VERSION ""

NS_ :

BS_:

BU_: AMS VCU

BO_ 3221225472 VECTOR__INDEPENDENT_SIG_MSG: 0 Vector__XXX
 SG_ NewSignal_0003 : 24|8@1+ (1,0) [0|0] "" Vector__XXX

BO_ 131 Start_PreCharge: 1 VCU
 SG_ Precharge_Request : 0|1@0+ (1,0) [0|0] "ON/OFF" Vector__XXX

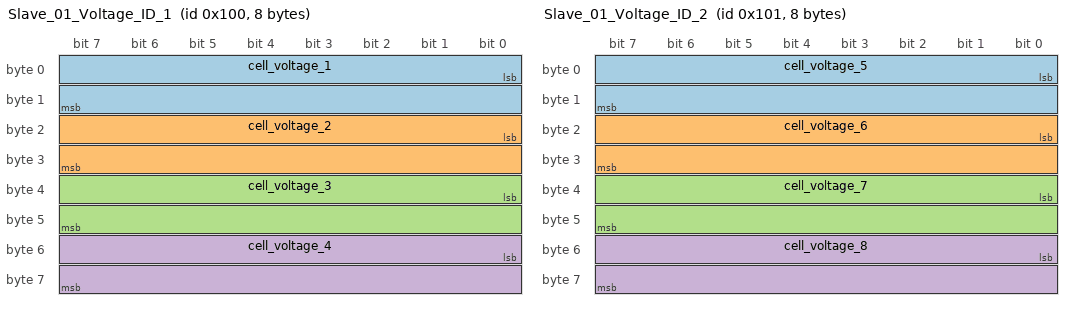
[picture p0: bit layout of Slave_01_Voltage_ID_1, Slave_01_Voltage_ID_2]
BO_ 256 Slave_01_Voltage_ID_1: 8 AMS
 SG_ cell_voltage_1 : 0|16@1+ (0.001,0) [0|0] "V" Vector__XXX
 SG_ cell_voltage_2 : 16|16@1+ (0.001,0) [0|0] "V" Vector__XXX
 SG_ cell_voltage_3 : 32|16@1+ (0.001,0) [0|0] "V" Vector__XXX
 SG_ cell_voltage_4 : 48|16@1+ (0.001,0) [0|0] "V" Vector__XXX

BO_ 257 Slave_01_Voltage_ID_2: 8 AMS
 SG_ cell_voltage_5 : 0|16@1+ (0.001,0) [0|0] "V" Vector__XXX
 SG_ cell_voltage_6 : 16|16@1+ (0.001,0) [0|0] "V" Vector__XXX
 SG_ cell_voltage_7 : 32|16@1+ (0.001,0) [0|0] "V" Vector__XXX
 SG_ cell_voltage_8 : 48|16@1+ (0.001,0) [0|0] "V" Vector__XXX

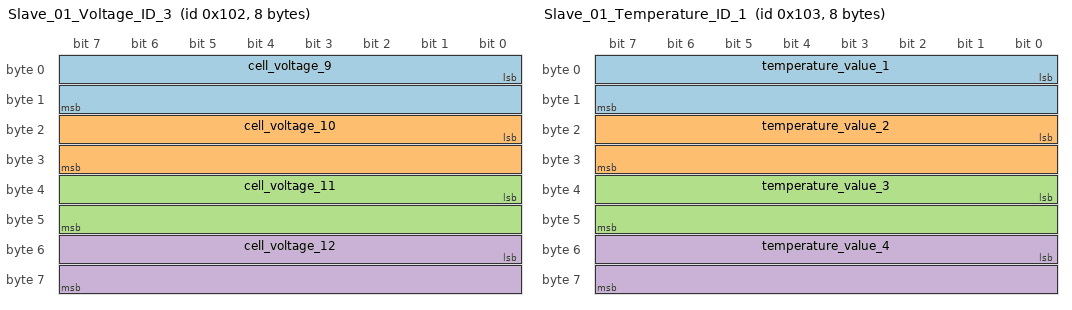
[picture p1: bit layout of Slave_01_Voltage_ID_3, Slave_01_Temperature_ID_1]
BO_ 258 Slave_01_Voltage_ID_3: 8 AMS
 SG_ cell_voltage_9 : 0|16@1+ (0.001,0) [0|0] "V" Vector__XXX
 SG_ cell_voltage_10 : 16|16@1+ (0.001,0) [0|0] "V" Vector__XXX
 SG_ cell_voltage_11 : 32|16@1+ (0.001,0) [0|0] "V" Vector__XXX
 SG_ cell_voltage_12 : 48|16@1+ (0.001,0) [0|0] "V" Vector__XXX

BO_ 259 Slave_01_Temperature_ID_1: 8 AMS
 SG_ temperature_value_1 : 0|16@1+ (0.01,0) [0|0] "ºC" Vector__XXX
 SG_ temperature_value_2 : 16|16@1+ (0.01,0) [0|0] "ºC" Vector__XXX
 SG_ temperature_value_3 : 32|16@1+ (0.01,0) [0|0] "ºC" Vector__XXX
 SG_ temperature_value_4 : 48|16@1+ (0.01,0) [0|0] "ºC" Vector__XXX

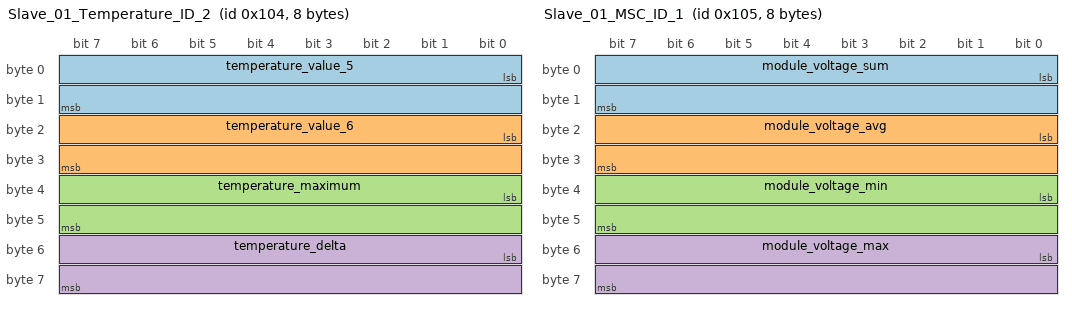
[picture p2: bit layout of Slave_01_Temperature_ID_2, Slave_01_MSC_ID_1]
BO_ 260 Slave_01_Temperature_ID_2: 8 AMS
 SG_ temperature_value_5 : 0|16@1+ (0.01,0) [0|0] "ºC" Vector__XXX
 SG_ temperature_value_6 : 16|16@1+ (0.01,0) [0|0] "ºC" Vector__XXX
 SG_ temperature_maximum : 32|16@1+ (0.01,0) [0|0] "ºC" Vector__XXX
 SG_ temperature_delta : 48|16@1+ (0.01,0) [0|0] "ºC" Vector__XXX

BO_ 261 Slave_01_MSC_ID_1: 8 AMS
 SG_ module_voltage_sum : 0|16@1+ (1,0) [0|0] "" Vector__XXX
 SG_ module_voltage_avg : 16|16@1+ (1,0) [0|0] "" Vector__XXX
 SG_ module_voltage_min : 32|16@1+ (1,0) [0|0] "" Vector__XXX
 SG_ module_voltage_max : 48|16@1+ (1,0) [0|0] "" Vector__XXX

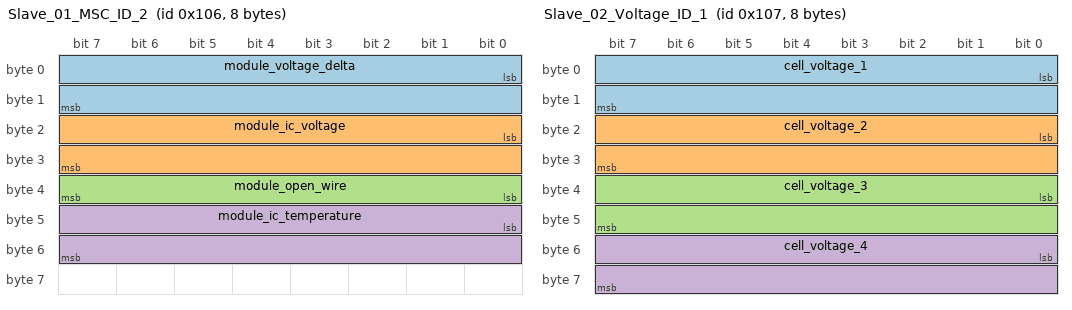
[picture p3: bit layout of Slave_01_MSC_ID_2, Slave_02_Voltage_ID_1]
BO_ 262 Slave_01_MSC_ID_2: 8 AMS
 SG_ module_voltage_delta : 0|16@1+ (1,0) [0|0] "" Vector__XXX
 SG_ module_ic_voltage : 16|16@1+ (1,0) [0|0] "" Vector__XXX
 SG_ module_open_wire : 32|8@1+ (1,0) [0|0] "" Vector__XXX
 SG_ module_ic_temperature : 40|16@1+ (1,0) [0|0] "" Vector__XXX

BO_ 263 Slave_02_Voltage_ID_1: 8 AMS
 SG_ cell_voltage_1 : 0|16@1+ (0.001,0) [0|0] "V" Vector__XXX
 SG_ cell_voltage_2 : 16|16@1+ (0.001,0) [0|0] "V" Vector__XXX
 SG_ cell_voltage_3 : 32|16@1+ (0.001,0) [0|0] "V" Vector__XXX
 SG_ cell_voltage_4 : 48|16@1+ (0.001,0) [0|0] "V" Vector__XXX

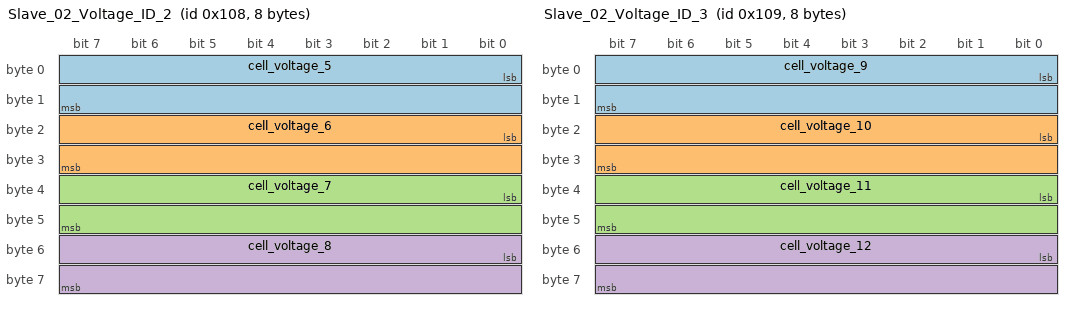
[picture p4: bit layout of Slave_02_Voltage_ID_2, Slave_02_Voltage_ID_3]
BO_ 264 Slave_02_Voltage_ID_2: 8 AMS
 SG_ cell_voltage_5 : 0|16@1+ (0.001,0) [0|0] "V" Vector__XXX
 SG_ cell_voltage_6 : 16|16@1+ (0.001,0) [0|0] "V" Vector__XXX
 SG_ cell_voltage_7 : 32|16@1+ (0.001,0) [0|0] "V" Vector__XXX
 SG_ cell_voltage_8 : 48|16@1+ (0.001,0) [0|0] "V" Vector__XXX

BO_ 265 Slave_02_Voltage_ID_3: 8 AMS
 SG_ cell_voltage_9 : 0|16@1+ (0.001,0) [0|0] "V" Vector__XXX
 SG_ cell_voltage_10 : 16|16@1+ (0.001,0) [0|0] "V" Vector__XXX
 SG_ cell_voltage_11 : 32|16@1+ (0.001,0) [0|0] "V" Vector__XXX
 SG_ cell_voltage_12 : 48|16@1+ (0.001,0) [0|0] "V" Vector__XXX

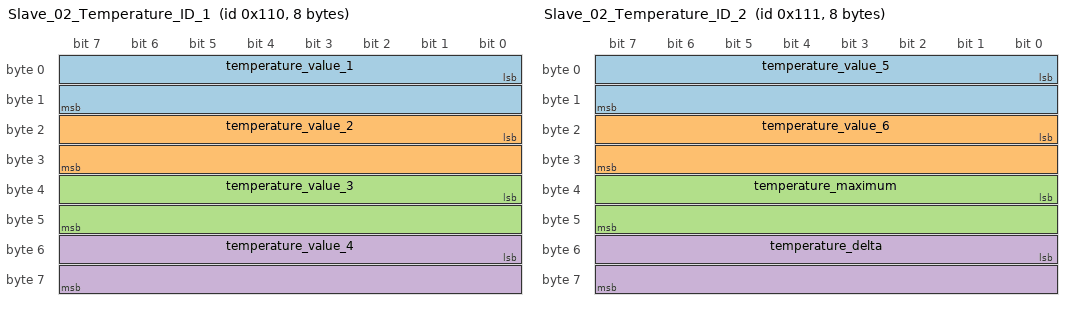
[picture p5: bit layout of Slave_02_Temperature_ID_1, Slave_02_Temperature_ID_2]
BO_ 272 Slave_02_Temperature_ID_1: 8 AMS
 SG_ temperature_value_1 : 0|16@1+ (0.01,0) [0|0] "ºC" Vector__XXX
 SG_ temperature_value_2 : 16|16@1+ (0.01,0) [0|0] "ºC" Vector__XXX
 SG_ temperature_value_3 : 32|16@1+ (0.01,0) [0|0] "ºC" Vector__XXX
 SG_ temperature_value_4 : 48|16@1+ (0.01,0) [0|0] "ºC" Vector__XXX

BO_ 273 Slave_02_Temperature_ID_2: 8 AMS
 SG_ temperature_value_5 : 0|16@1+ (0.01,0) [0|0] "ºC" Vector__XXX
 SG_ temperature_value_6 : 16|16@1+ (0.01,0) [0|0] "ºC" Vector__XXX
 SG_ temperature_maximum : 32|16@1+ (0.01,0) [0|0] "ºC" Vector__XXX
 SG_ temperature_delta : 48|16@1+ (0.01,0) [0|0] "ºC" Vector__XXX

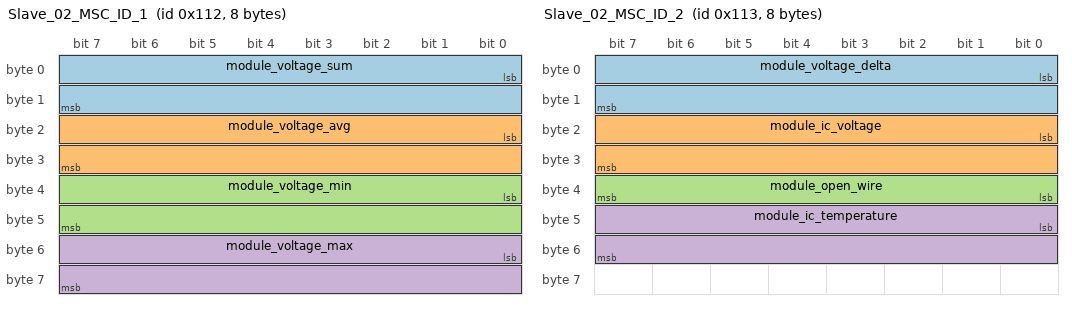
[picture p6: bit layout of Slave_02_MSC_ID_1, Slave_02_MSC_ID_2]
BO_ 274 Slave_02_MSC_ID_1: 8 AMS
 SG_ module_voltage_sum : 0|16@1+ (1,0) [0|0] "" Vector__XXX
 SG_ module_voltage_avg : 16|16@1+ (1,0) [0|0] "" Vector__XXX
 SG_ module_voltage_min : 32|16@1+ (1,0) [0|0] "" Vector__XXX
 SG_ module_voltage_max : 48|16@1+ (1,0) [0|0] "" Vector__XXX

BO_ 275 Slave_02_MSC_ID_2: 8 AMS
 SG_ module_voltage_delta : 0|16@1+ (1,0) [0|0] "" Vector__XXX
 SG_ module_ic_voltage : 16|16@1+ (1,0) [0|0] "" Vector__XXX
 SG_ module_open_wire : 32|8@1+ (1,0) [0|0] "" Vector__XXX
 SG_ module_ic_temperature : 40|16@1+ (1,0) [0|0] "" Vector__XXX

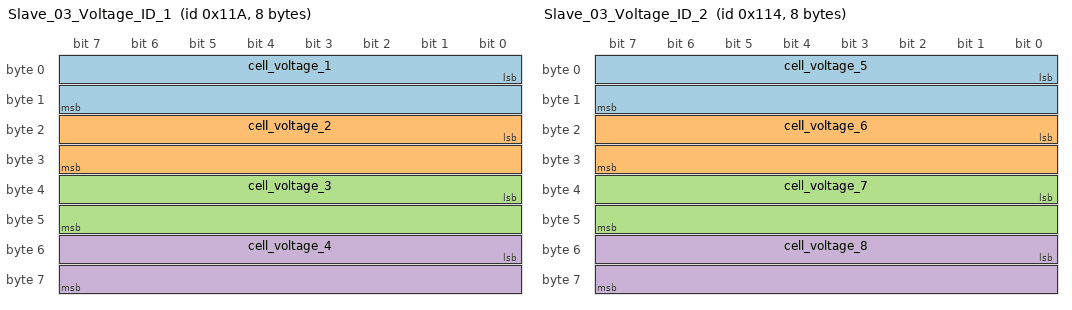
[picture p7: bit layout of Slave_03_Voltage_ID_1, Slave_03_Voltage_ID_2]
BO_ 282 Slave_03_Voltage_ID_1: 8 AMS
 SG_ cell_voltage_1 : 0|16@1+ (0.001,0) [0|0] "V" Vector__XXX
 SG_ cell_voltage_2 : 16|16@1+ (0.001,0) [0|0] "V" Vector__XXX
 SG_ cell_voltage_3 : 32|16@1+ (0.001,0) [0|0] "V" Vector__XXX
 SG_ cell_voltage_4 : 48|16@1+ (0.001,0) [0|0] "V" Vector__XXX

BO_ 276 Slave_03_Voltage_ID_2: 8 AMS
 SG_ cell_voltage_5 : 0|16@1+ (0.001,0) [0|0] "V" Vector__XXX
 SG_ cell_voltage_6 : 16|16@1+ (0.001,0) [0|0] "V" Vector__XXX
 SG_ cell_voltage_7 : 32|16@1+ (0.001,0) [0|0] "V" Vector__XXX
 SG_ cell_voltage_8 : 48|16@1+ (0.001,0) [0|0] "V" Vector__XXX

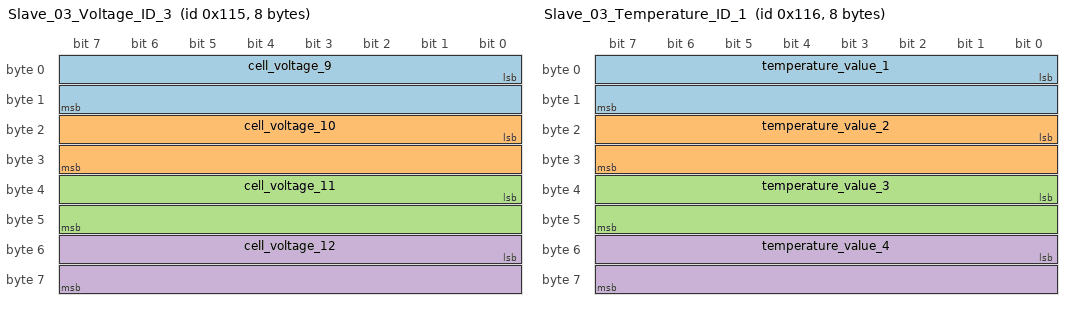
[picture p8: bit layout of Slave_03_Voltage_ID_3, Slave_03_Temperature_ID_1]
BO_ 277 Slave_03_Voltage_ID_3: 8 AMS
 SG_ cell_voltage_9 : 0|16@1+ (0.001,0) [0|0] "V" Vector__XXX
 SG_ cell_voltage_10 : 16|16@1+ (0.001,0) [0|0] "V" Vector__XXX
 SG_ cell_voltage_11 : 32|16@1+ (0.001,0) [0|0] "V" Vector__XXX
 SG_ cell_voltage_12 : 48|16@1+ (0.001,0) [0|0] "V" Vector__XXX

BO_ 278 Slave_03_Temperature_ID_1: 8 AMS
 SG_ temperature_value_1 : 0|16@1+ (0.01,0) [0|0] "ºC" Vector__XXX
 SG_ temperature_value_2 : 16|16@1+ (0.01,0) [0|0] "ºC" Vector__XXX
 SG_ temperature_value_3 : 32|16@1+ (0.01,0) [0|0] "ºC" Vector__XXX
 SG_ temperature_value_4 : 48|16@1+ (0.01,0) [0|0] "ºC" Vector__XXX

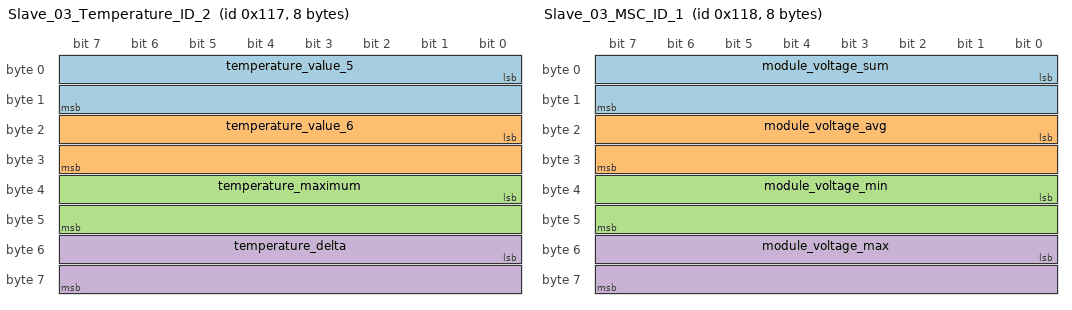
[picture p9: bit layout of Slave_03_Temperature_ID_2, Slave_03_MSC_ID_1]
BO_ 279 Slave_03_Temperature_ID_2: 8 AMS
 SG_ temperature_value_5 : 0|16@1+ (0.01,0) [0|0] "ºC" Vector__XXX
 SG_ temperature_value_6 : 16|16@1+ (0.01,0) [0|0] "ºC" Vector__XXX
 SG_ temperature_maximum : 32|16@1+ (0.01,0) [0|0] "ºC" Vector__XXX
 SG_ temperature_delta : 48|16@1+ (0.01,0) [0|0] "ºC" Vector__XXX

BO_ 280 Slave_03_MSC_ID_1: 8 AMS
 SG_ module_voltage_sum : 0|16@1+ (1,0) [0|0] "" Vector__XXX
 SG_ module_voltage_avg : 16|16@1+ (1,0) [0|0] "" Vector__XXX
 SG_ module_voltage_min : 32|16@1+ (1,0) [0|0] "" Vector__XXX
 SG_ module_voltage_max : 48|16@1+ (1,0) [0|0] "" Vector__XXX

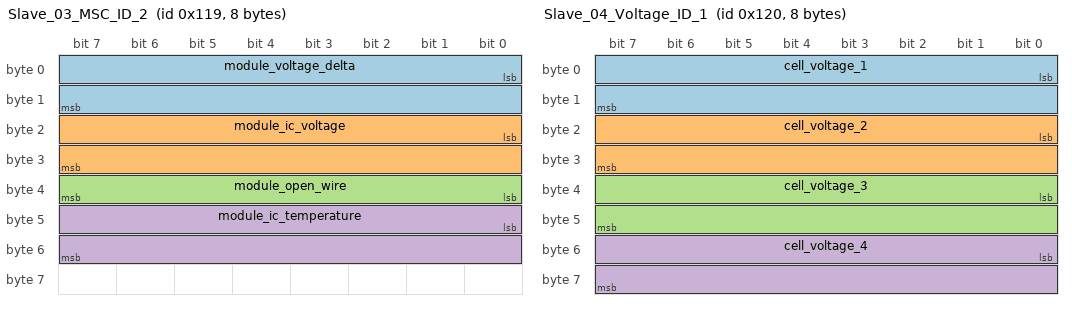
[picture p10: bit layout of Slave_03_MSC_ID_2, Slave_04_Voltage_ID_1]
BO_ 281 Slave_03_MSC_ID_2: 8 AMS
 SG_ module_voltage_delta : 0|16@1+ (1,0) [0|0] "" Vector__XXX
 SG_ module_ic_voltage : 16|16@1+ (1,0) [0|0] "" Vector__XXX
 SG_ module_open_wire : 32|8@1+ (1,0) [0|0] "" Vector__XXX
 SG_ module_ic_temperature : 40|16@1+ (1,0) [0|0] "" Vector__XXX

BO_ 288 Slave_04_Voltage_ID_1: 8 AMS
 SG_ cell_voltage_1 : 0|16@1+ (0.001,0) [0|0] "V" Vector__XXX
 SG_ cell_voltage_2 : 16|16@1+ (0.001,0) [0|0] "V" Vector__XXX
 SG_ cell_voltage_3 : 32|16@1+ (0.001,0) [0|0] "V" Vector__XXX
 SG_ cell_voltage_4 : 48|16@1+ (0.001,0) [0|0] "V" Vector__XXX

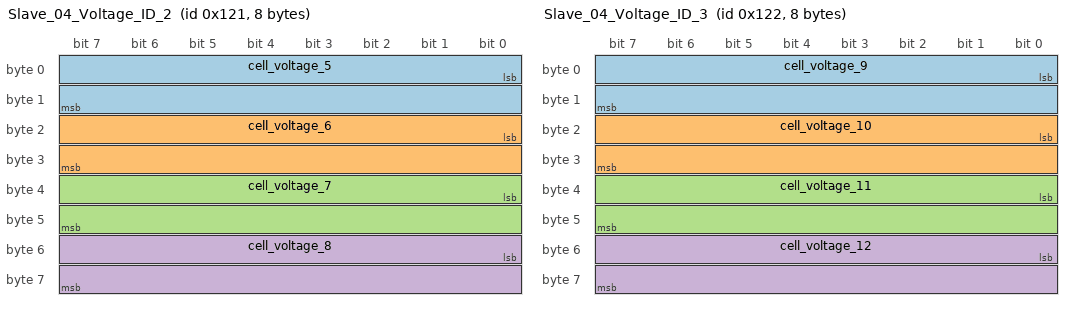
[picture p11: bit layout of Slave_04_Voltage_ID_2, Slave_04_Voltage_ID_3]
BO_ 289 Slave_04_Voltage_ID_2: 8 AMS
 SG_ cell_voltage_5 : 0|16@1+ (0.001,0) [0|0] "V" Vector__XXX
 SG_ cell_voltage_6 : 16|16@1+ (0.001,0) [0|0] "V" Vector__XXX
 SG_ cell_voltage_7 : 32|16@1+ (0.001,0) [0|0] "V" Vector__XXX
 SG_ cell_voltage_8 : 48|16@1+ (0.001,0) [0|0] "V" Vector__XXX

BO_ 290 Slave_04_Voltage_ID_3: 8 AMS
 SG_ cell_voltage_9 : 0|16@1+ (0.001,0) [0|0] "V" Vector__XXX
 SG_ cell_voltage_10 : 16|16@1+ (0.001,0) [0|0] "V" Vector__XXX
 SG_ cell_voltage_11 : 32|16@1+ (0.001,0) [0|0] "V" Vector__XXX
 SG_ cell_voltage_12 : 48|16@1+ (0.001,0) [0|0] "V" Vector__XXX

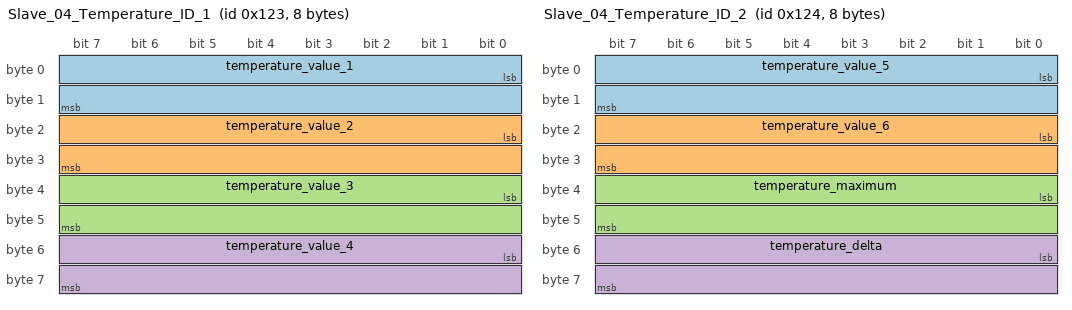
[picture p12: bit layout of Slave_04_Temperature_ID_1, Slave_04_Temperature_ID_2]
BO_ 291 Slave_04_Temperature_ID_1: 8 AMS
 SG_ temperature_value_1 : 0|16@1+ (0.01,0) [0|0] "ºC" Vector__XXX
 SG_ temperature_value_2 : 16|16@1+ (0.01,0) [0|0] "ºC" Vector__XXX
 SG_ temperature_value_3 : 32|16@1+ (0.01,0) [0|0] "ºC" Vector__XXX
 SG_ temperature_value_4 : 48|16@1+ (0.01,0) [0|0] "ºC" Vector__XXX

BO_ 292 Slave_04_Temperature_ID_2: 8 AMS
 SG_ temperature_value_5 : 0|16@1+ (0.01,0) [0|0] "ºC" Vector__XXX
 SG_ temperature_value_6 : 16|16@1+ (0.01,0) [0|0] "ºC" Vector__XXX
 SG_ temperature_maximum : 32|16@1+ (0.01,0) [0|0] "ºC" Vector__XXX
 SG_ temperature_delta : 48|16@1+ (0.01,0) [0|0] "ºC" Vector__XXX

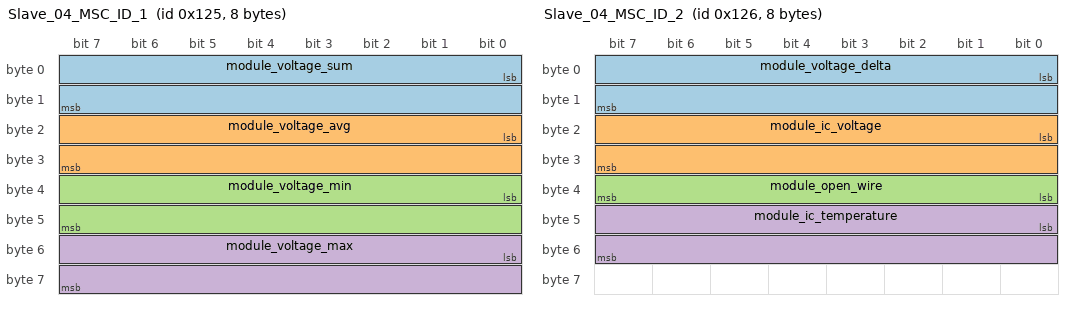
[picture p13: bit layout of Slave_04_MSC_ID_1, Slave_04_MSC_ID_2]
BO_ 293 Slave_04_MSC_ID_1: 8 AMS
 SG_ module_voltage_sum : 0|16@1+ (1,0) [0|0] "" Vector__XXX
 SG_ module_voltage_avg : 16|16@1+ (1,0) [0|0] "" Vector__XXX
 SG_ module_voltage_min : 32|16@1+ (1,0) [0|0] "" Vector__XXX
 SG_ module_voltage_max : 48|16@1+ (1,0) [0|0] "" Vector__XXX

BO_ 294 Slave_04_MSC_ID_2: 8 AMS
 SG_ module_voltage_delta : 0|16@1+ (1,0) [0|0] "" Vector__XXX
 SG_ module_ic_voltage : 16|16@1+ (1,0) [0|0] "" Vector__XXX
 SG_ module_open_wire : 32|8@1+ (1,0) [0|0] "" Vector__XXX
 SG_ module_ic_temperature : 40|16@1+ (1,0) [0|0] "" Vector__XXX

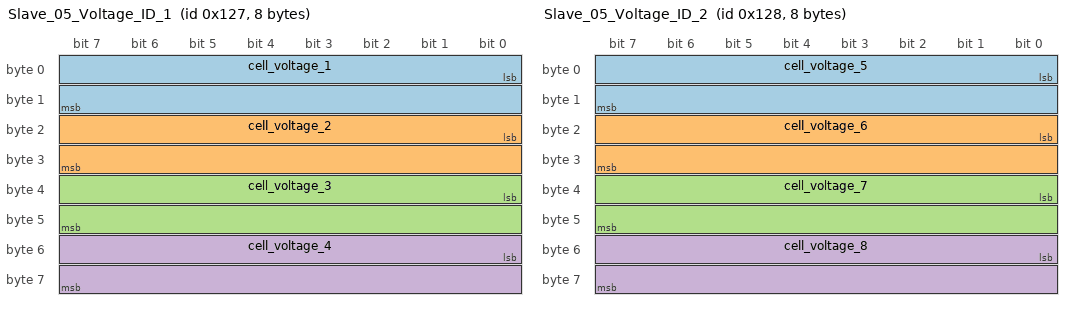
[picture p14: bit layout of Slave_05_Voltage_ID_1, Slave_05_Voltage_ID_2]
BO_ 295 Slave_05_Voltage_ID_1: 8 AMS
 SG_ cell_voltage_1 : 0|16@1+ (0.001,0) [0|0] "V" Vector__XXX
 SG_ cell_voltage_2 : 16|16@1+ (0.001,0) [0|0] "V" Vector__XXX
 SG_ cell_voltage_3 : 32|16@1+ (0.001,0) [0|0] "V" Vector__XXX
 SG_ cell_voltage_4 : 48|16@1+ (0.001,0) [0|0] "V" Vector__XXX

BO_ 296 Slave_05_Voltage_ID_2: 8 AMS
 SG_ cell_voltage_5 : 0|16@1+ (0.001,0) [0|0] "V" Vector__XXX
 SG_ cell_voltage_6 : 16|16@1+ (0.001,0) [0|0] "V" Vector__XXX
 SG_ cell_voltage_7 : 32|16@1+ (0.001,0) [0|0] "V" Vector__XXX
 SG_ cell_voltage_8 : 48|16@1+ (0.001,0) [0|0] "V" Vector__XXX

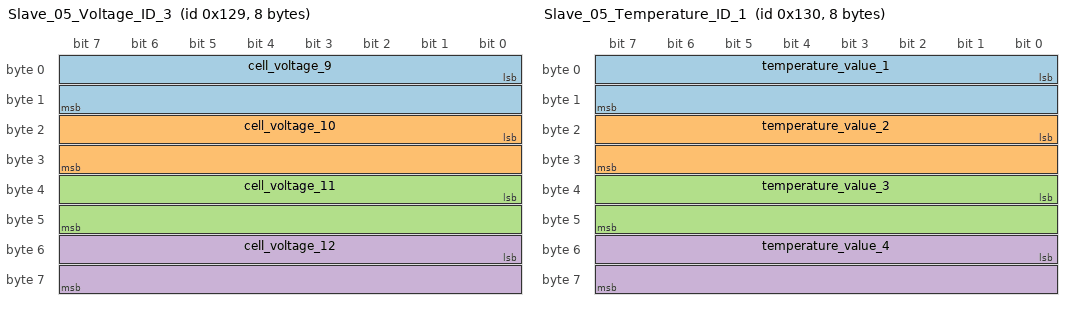
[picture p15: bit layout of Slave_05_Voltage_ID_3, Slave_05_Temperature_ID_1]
BO_ 297 Slave_05_Voltage_ID_3: 8 AMS
 SG_ cell_voltage_9 : 0|16@1+ (0.001,0) [0|0] "V" Vector__XXX
 SG_ cell_voltage_10 : 16|16@1+ (0.001,0) [0|0] "V" Vector__XXX
 SG_ cell_voltage_11 : 32|16@1+ (0.001,0) [0|0] "V" Vector__XXX
 SG_ cell_voltage_12 : 48|16@1+ (0.001,0) [0|0] "V" Vector__XXX

BO_ 304 Slave_05_Temperature_ID_1: 8 AMS
 SG_ temperature_value_1 : 0|16@1+ (0.01,0) [0|0] "ºC" Vector__XXX
 SG_ temperature_value_2 : 16|16@1+ (0.01,0) [0|0] "ºC" Vector__XXX
 SG_ temperature_value_3 : 32|16@1+ (0.01,0) [0|0] "ºC" Vector__XXX
 SG_ temperature_value_4 : 48|16@1+ (0.01,0) [0|0] "ºC" Vector__XXX

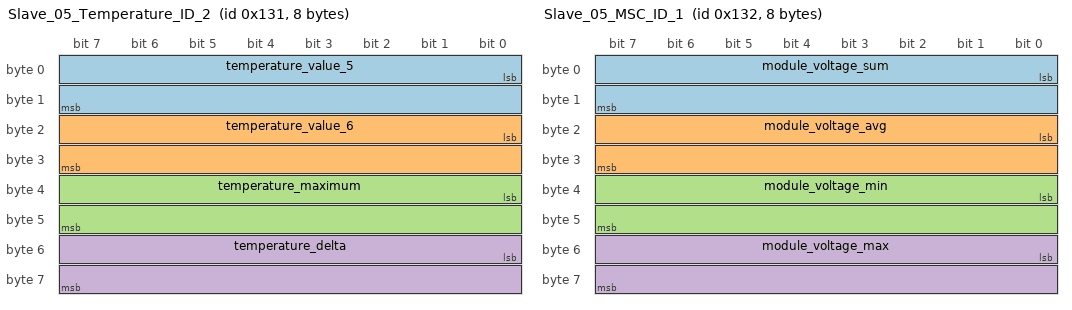
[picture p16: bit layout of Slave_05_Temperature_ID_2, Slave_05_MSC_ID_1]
BO_ 305 Slave_05_Temperature_ID_2: 8 AMS
 SG_ temperature_value_5 : 0|16@1+ (0.01,0) [0|0] "ºC" Vector__XXX
 SG_ temperature_value_6 : 16|16@1+ (0.01,0) [0|0] "ºC" Vector__XXX
 SG_ temperature_maximum : 32|16@1+ (0.01,0) [0|0] "ºC" Vector__XXX
 SG_ temperature_delta : 48|16@1+ (0.01,0) [0|0] "ºC" Vector__XXX

BO_ 306 Slave_05_MSC_ID_1: 8 AMS
 SG_ module_voltage_sum : 0|16@1+ (1,0) [0|0] "" Vector__XXX
 SG_ module_voltage_avg : 16|16@1+ (1,0) [0|0] "" Vector__XXX
 SG_ module_voltage_min : 32|16@1+ (1,0) [0|0] "" Vector__XXX
 SG_ module_voltage_max : 48|16@1+ (1,0) [0|0] "" Vector__XXX

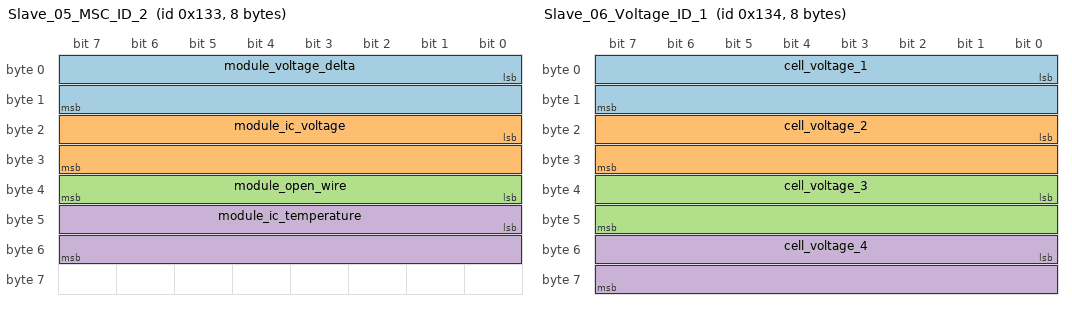
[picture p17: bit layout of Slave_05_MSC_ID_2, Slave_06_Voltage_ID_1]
BO_ 307 Slave_05_MSC_ID_2: 8 AMS
 SG_ module_voltage_delta : 0|16@1+ (1,0) [0|0] "" Vector__XXX
 SG_ module_ic_voltage : 16|16@1+ (1,0) [0|0] "" Vector__XXX
 SG_ module_open_wire : 32|8@1+ (1,0) [0|0] "" Vector__XXX
 SG_ module_ic_temperature : 40|16@1+ (1,0) [0|0] "" Vector__XXX

BO_ 308 Slave_06_Voltage_ID_1: 8 AMS
 SG_ cell_voltage_1 : 0|16@1+ (0.001,0) [0|0] "V" Vector__XXX
 SG_ cell_voltage_2 : 16|16@1+ (0.001,0) [0|0] "V" Vector__XXX
 SG_ cell_voltage_3 : 32|16@1+ (0.001,0) [0|0] "V" Vector__XXX
 SG_ cell_voltage_4 : 48|16@1+ (0.001,0) [0|0] "V" Vector__XXX

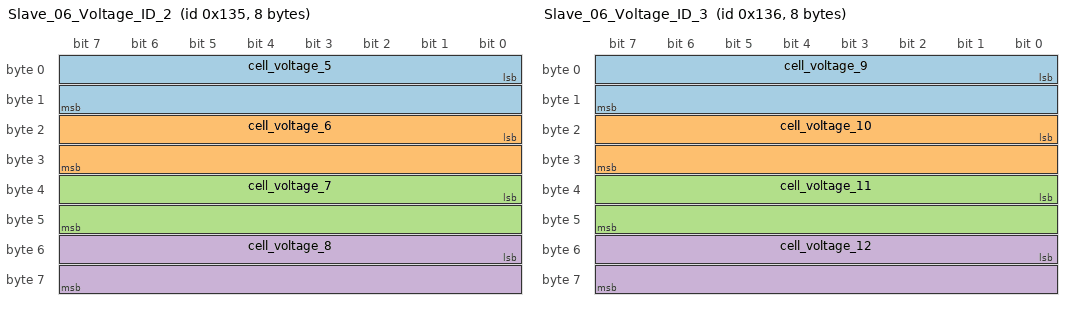
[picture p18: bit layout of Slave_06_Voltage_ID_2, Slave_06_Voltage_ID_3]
BO_ 309 Slave_06_Voltage_ID_2: 8 AMS
 SG_ cell_voltage_5 : 0|16@1+ (0.001,0) [0|0] "V" Vector__XXX
 SG_ cell_voltage_6 : 16|16@1+ (0.001,0) [0|0] "V" Vector__XXX
 SG_ cell_voltage_7 : 32|16@1+ (0.001,0) [0|0] "V" Vector__XXX
 SG_ cell_voltage_8 : 48|16@1+ (0.001,0) [0|0] "V" Vector__XXX

BO_ 310 Slave_06_Voltage_ID_3: 8 AMS
 SG_ cell_voltage_9 : 0|16@1+ (0.001,0) [0|0] "V" Vector__XXX
 SG_ cell_voltage_10 : 16|16@1+ (0.001,0) [0|0] "V" Vector__XXX
 SG_ cell_voltage_11 : 32|16@1+ (0.001,0) [0|0] "V" Vector__XXX
 SG_ cell_voltage_12 : 48|16@1+ (0.001,0) [0|0] "V" Vector__XXX

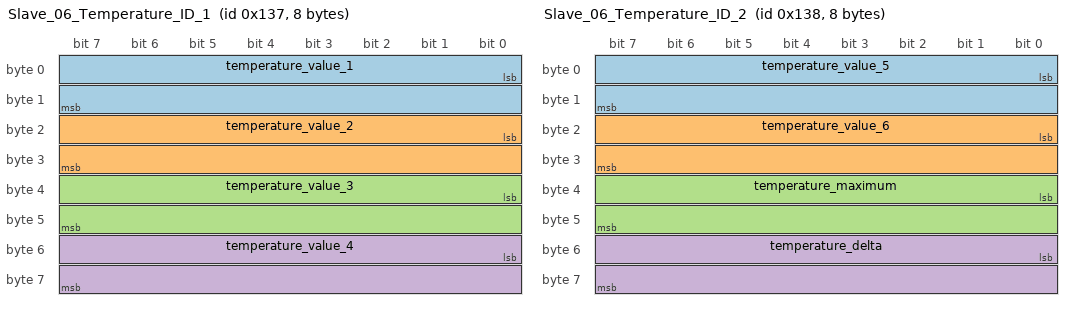
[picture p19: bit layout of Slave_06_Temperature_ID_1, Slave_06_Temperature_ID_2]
BO_ 311 Slave_06_Temperature_ID_1: 8 AMS
 SG_ temperature_value_1 : 0|16@1+ (0.01,0) [0|0] "ºC" Vector__XXX
 SG_ temperature_value_2 : 16|16@1+ (0.01,0) [0|0] "ºC" Vector__XXX
 SG_ temperature_value_3 : 32|16@1+ (0.01,0) [0|0] "ºC" Vector__XXX
 SG_ temperature_value_4 : 48|16@1+ (0.01,0) [0|0] "ºC" Vector__XXX

BO_ 312 Slave_06_Temperature_ID_2: 8 AMS
 SG_ temperature_value_5 : 0|16@1+ (0.01,0) [0|0] "ºC" Vector__XXX
 SG_ temperature_value_6 : 16|16@1+ (0.01,0) [0|0] "ºC" Vector__XXX
 SG_ temperature_maximum : 32|16@1+ (0.01,0) [0|0] "ºC" Vector__XXX
 SG_ temperature_delta : 48|16@1+ (0.01,0) [0|0] "ºC" Vector__XXX

BO_ 313 Slave_06_MSC_ID_1: 8 AMS
 SG_ module_voltage_sum : 0|16@1+ (1,0) [0|0] "" Vector__XXX
 SG_ module_voltage_avg : 16|16@1+ (1,0) [0|0] "" Vector__XXX
 SG_ module_voltage_min : 32|16@1+ (1,0) [0|0] "" Vector__XXX
 SG_ module_voltage_max : 48|16@1+ (1,0) [0|0] "" Vector__XXX

BO_ 320 Slave_06_MSC_ID_2: 8 AMS
 SG_ module_voltage_delta : 0|16@1+ (1,0) [0|0] "" Vector__XXX
 SG_ module_ic_voltage : 16|16@1+ (1,0) [0|0] "" Vector__XXX
 SG_ module_open_wire : 32|8@1+ (1,0) [0|0] "" Vector__XXX
 SG_ module_ic_temperature : 40|16@1+ (1,0) [0|0] "" Vector__XXX

BO_ 321 Slave_07_Voltage_ID_1: 8 AMS
 SG_ cell_voltage_1 : 0|16@1+ (0.001,0) [0|0] "V" Vector__XXX
 SG_ cell_voltage_2 : 16|16@1+ (0.001,0) [0|0] "V" Vector__XXX
 SG_ cell_voltage_3 : 32|16@1+ (0.001,0) [0|0] "V" Vector__XXX
 SG_ cell_voltage_4 : 48|16@1+ (0.001,0) [0|0] "V" Vector__XXX

BO_ 322 Slave_07_Voltage_ID_2: 8 AMS
 SG_ cell_voltage_5 : 0|16@1+ (0.001,0) [0|0] "V" Vector__XXX
 SG_ cell_voltage_6 : 16|16@1+ (0.001,0) [0|0] "V" Vector__XXX
 SG_ cell_voltage_7 : 32|16@1+ (0.001,0) [0|0] "V" Vector__XXX
 SG_ cell_voltage_8 : 48|16@1+ (0.001,0) [0|0] "V" Vector__XXX

BO_ 323 Slave_07_Voltage_ID_3: 8 AMS
 SG_ cell_voltage_9 : 0|16@1+ (0.001,0) [0|0] "V" Vector__XXX
 SG_ cell_voltage_10 : 16|16@1+ (0.001,0) [0|0] "V" Vector__XXX
 SG_ cell_voltage_11 : 32|16@1+ (0.001,0) [0|0] "V" Vector__XXX
 SG_ cell_voltage_12 : 48|16@1+ (0.001,0) [0|0] "V" Vector__XXX

BO_ 324 Slave_07_Temperature_ID_1: 8 AMS
 SG_ temperature_value_1 : 0|16@1+ (0.01,0) [0|0] "ºC" Vector__XXX
 SG_ temperature_value_2 : 16|16@1+ (0.01,0) [0|0] "ºC" Vector__XXX
 SG_ temperature_value_3 : 32|16@1+ (0.01,0) [0|0] "ºC" Vector__XXX
 SG_ temperature_value_4 : 48|16@1+ (0.01,0) [0|0] "ºC" Vector__XXX

BO_ 325 Slave_07_Temperature_ID_2: 8 AMS
 SG_ temperature_value_5 : 0|16@1+ (0.01,0) [0|0] "ºC" Vector__XXX
 SG_ temperature_value_6 : 16|16@1+ (0.01,0) [0|0] "ºC" Vector__XXX
 SG_ temperature_maximum : 32|16@1+ (0.01,0) [0|0] "ºC" Vector__XXX
 SG_ temperature_delta : 48|16@1+ (0.01,0) [0|0] "ºC" Vector__XXX

BO_ 326 Slave_07_MSC_ID_1: 8 AMS
 SG_ module_voltage_sum : 0|16@1+ (1,0) [0|0] "" Vector__XXX
 SG_ module_voltage_avg : 16|16@1+ (1,0) [0|0] "" Vector__XXX
 SG_ module_voltage_min : 32|16@1+ (1,0) [0|0] "" Vector__XXX
 SG_ module_voltage_max : 48|16@1+ (1,0) [0|0] "" Vector__XXX

BO_ 327 Slave_07_MSC_ID_2: 8 AMS
 SG_ module_voltage_delta : 0|16@1+ (1,0) [0|0] "" Vector__XXX
 SG_ module_ic_voltage : 16|16@1+ (1,0) [0|0] "" Vector__XXX
 SG_ module_open_wire : 32|8@1+ (1,0) [0|0] "" Vector__XXX
 SG_ module_ic_temperature : 40|16@1+ (1,0) [0|0] "" Vector__XXX

BO_ 328 Slave_08_Voltage_ID_1: 8 AMS
 SG_ cell_voltage_1 : 0|16@1+ (0.001,0) [0|0] "V" Vector__XXX
 SG_ cell_voltage_2 : 16|16@1+ (0.001,0) [0|0] "V" Vector__XXX
 SG_ cell_voltage_3 : 32|16@1+ (0.001,0) [0|0] "V" Vector__XXX
 SG_ cell_voltage_4 : 48|16@1+ (0.001,0) [0|0] "V" Vector__XXX

BO_ 329 Slave_08_Voltage_ID_2: 8 AMS
 SG_ cell_voltage_5 : 0|16@1+ (0.001,0) [0|0] "V" Vector__XXX
 SG_ cell_voltage_6 : 16|16@1+ (0.001,0) [0|0] "V" Vector__XXX
 SG_ cell_voltage_7 : 32|16@1+ (0.001,0) [0|0] "V" Vector__XXX
 SG_ cell_voltage_8 : 48|16@1+ (0.001,0) [0|0] "V" Vector__XXX

BO_ 336 Slave_08_Voltage_ID_3: 8 AMS
 SG_ cell_voltage_9 : 0|16@1+ (0.001,0) [0|0] "V" Vector__XXX
 SG_ cell_voltage_10 : 16|16@1+ (0.001,0) [0|0] "V" Vector__XXX
 SG_ cell_voltage_11 : 32|16@1+ (0.001,0) [0|0] "V" Vector__XXX
 SG_ cell_voltage_12 : 48|16@1+ (0.001,0) [0|0] "V" Vector__XXX

BO_ 337 Slave_08_Temperature_ID_1: 8 AMS
 SG_ temperature_value_1 : 0|16@1+ (0.01,0) [0|0] "ºC" Vector__XXX
 SG_ temperature_value_2 : 16|16@1+ (0.01,0) [0|0] "ºC" Vector__XXX
 SG_ temperature_value_3 : 32|16@1+ (0.01,0) [0|0] "ºC" Vector__XXX
 SG_ temperature_value_4 : 48|16@1+ (0.01,0) [0|0] "ºC" Vector__XXX

BO_ 338 Slave_08_Temperature_ID_2: 8 AMS
 SG_ temperature_value_5 : 0|16@1+ (0.01,0) [0|0] "ºC" Vector__XXX
 SG_ temperature_value_6 : 16|16@1+ (0.01,0) [0|0] "ºC" Vector__XXX
 SG_ temperature_maximum : 32|16@1+ (0.01,0) [0|0] "ºC" Vector__XXX
 SG_ temperature_delta : 48|16@1+ (0.01,0) [0|0] "ºC" Vector__XXX

BO_ 339 Slave_08_MSC_ID_1: 8 AMS
 SG_ module_voltage_sum : 0|16@1+ (1,0) [0|0] "" Vector__XXX
 SG_ module_voltage_avg : 16|16@1+ (1,0) [0|0] "" Vector__XXX
 SG_ module_voltage_min : 32|16@1+ (1,0) [0|0] "" Vector__XXX
 SG_ module_voltage_max : 48|16@1+ (1,0) [0|0] "" Vector__XXX

BO_ 340 Slave_08_MSC_ID_2: 8 AMS
 SG_ module_voltage_delta : 0|16@1+ (1,0) [0|0] "" Vector__XXX
 SG_ module_ic_voltage : 16|16@1+ (1,0) [0|0] "" Vector__XXX
 SG_ module_open_wire : 32|8@1+ (1,0) [0|0] "" Vector__XXX
 SG_ module_ic_temperature : 40|16@1+ (1,0) [0|0] "" Vector__XXX

BO_ 341 Slave_09_Voltage_ID_1: 8 AMS
 SG_ cell_voltage_1 : 0|16@1+ (0.001,0) [0|0] "V" Vector__XXX
 SG_ cell_voltage_2 : 16|16@1+ (0.001,0) [0|0] "V" Vector__XXX
 SG_ cell_voltage_3 : 32|16@1+ (0.001,0) [0|0] "V" Vector__XXX
 SG_ cell_voltage_4 : 48|16@1+ (0.001,0) [0|0] "V" Vector__XXX

BO_ 342 Slave_09_Voltage_ID_2: 8 AMS
 SG_ cell_voltage_5 : 0|16@1+ (0.001,0) [0|0] "V" Vector__XXX
 SG_ cell_voltage_6 : 16|16@1+ (0.001,0) [0|0] "V" Vector__XXX
 SG_ cell_voltage_7 : 32|16@1+ (0.001,0) [0|0] "V" Vector__XXX
 SG_ cell_voltage_8 : 48|16@1+ (0.001,0) [0|0] "V" Vector__XXX

BO_ 343 Slave_09_Voltage_ID_3: 8 AMS
 SG_ cell_voltage_9 : 0|16@1+ (0.001,0) [0|0] "V" Vector__XXX
 SG_ cell_voltage_10 : 16|16@1+ (0.001,0) [0|0] "V" Vector__XXX
 SG_ cell_voltage_11 : 32|16@1+ (0.001,0) [0|0] "V" Vector__XXX
 SG_ cell_voltage_12 : 48|16@1+ (0.001,0) [0|0] "V" Vector__XXX

BO_ 344 Slave_09_Temperature_ID_1: 8 AMS
 SG_ temperature_value_1 : 0|16@1+ (0.01,0) [0|0] "ºC" Vector__XXX
 SG_ temperature_value_2 : 16|16@1+ (0.01,0) [0|0] "ºC" Vector__XXX
 SG_ temperature_value_3 : 32|16@1+ (0.01,0) [0|0] "ºC" Vector__XXX
 SG_ temperature_value_4 : 48|16@1+ (0.01,0) [0|0] "ºC" Vector__XXX

BO_ 345 Slave_09_Temperature_ID_2: 8 AMS
 SG_ temperature_value_5 : 0|16@1+ (0.01,0) [0|0] "ºC" Vector__XXX
 SG_ temperature_value_6 : 16|16@1+ (0.01,0) [0|0] "ºC" Vector__XXX
 SG_ temperature_maximum : 32|16@1+ (0.01,0) [0|0] "ºC" Vector__XXX
 SG_ temperature_delta : 48|16@1+ (0.01,0) [0|0] "ºC" Vector__XXX

BO_ 352 Slave_09_MSC_ID_1: 8 AMS
 SG_ module_voltage_sum : 0|16@1+ (1,0) [0|0] "" Vector__XXX
 SG_ module_voltage_avg : 16|16@1+ (1,0) [0|0] "" Vector__XXX
 SG_ module_voltage_min : 32|16@1+ (1,0) [0|0] "" Vector__XXX
 SG_ module_voltage_max : 48|16@1+ (1,0) [0|0] "" Vector__XXX

BO_ 353 Slave_09_MSC_ID_2: 8 AMS
 SG_ module_voltage_delta : 0|16@1+ (1,0) [0|0] "" Vector__XXX
 SG_ module_ic_voltage : 16|16@1+ (1,0) [0|0] "" Vector__XXX
 SG_ module_open_wire : 32|8@1+ (1,0) [0|0] "" Vector__XXX
 SG_ module_ic_temperature : 40|16@1+ (1,0) [0|0] "" Vector__XXX

BO_ 354 Slave_10_Voltage_ID_1: 8 AMS
 SG_ cell_voltage_1 : 0|16@1+ (0.001,0) [0|0] "V" Vector__XXX
 SG_ cell_voltage_2 : 16|16@1+ (0.001,0) [0|0] "V" Vector__XXX
 SG_ cell_voltage_3 : 32|16@1+ (0.001,0) [0|0] "V" Vector__XXX
 SG_ cell_voltage_4 : 48|16@1+ (0.001,0) [0|0] "V" Vector__XXX

BO_ 355 Slave_10_Voltage_ID_2: 8 AMS
 SG_ cell_voltage_5 : 0|16@1+ (0.001,0) [0|0] "V" Vector__XXX
 SG_ cell_voltage_6 : 16|16@1+ (0.001,0) [0|0] "V" Vector__XXX
 SG_ cell_voltage_7 : 32|16@1+ (0.001,0) [0|0] "V" Vector__XXX
 SG_ cell_voltage_8 : 48|16@1+ (0.001,0) [0|0] "V" Vector__XXX

BO_ 356 Slave_10_Voltage_ID_3: 8 AMS
 SG_ cell_voltage_9 : 0|16@1+ (0.001,0) [0|0] "V" Vector__XXX
 SG_ cell_voltage_10 : 16|16@1+ (0.001,0) [0|0] "V" Vector__XXX
 SG_ cell_voltage_11 : 32|16@1+ (0.001,0) [0|0] "V" Vector__XXX
 SG_ cell_voltage_12 : 48|16@1+ (0.001,0) [0|0] "V" Vector__XXX

BO_ 357 Slave_10_Temperature_ID_1: 8 AMS
 SG_ temperature_value_1 : 0|16@1+ (0.01,0) [0|0] "ºC" Vector__XXX
 SG_ temperature_value_2 : 16|16@1+ (0.01,0) [0|0] "ºC" Vector__XXX
 SG_ temperature_value_3 : 32|16@1+ (0.01,0) [0|0] "ºC" Vector__XXX
 SG_ temperature_value_4 : 48|16@1+ (0.01,0) [0|0] "ºC" Vector__XXX

BO_ 358 Slave_10_Temperature_ID_2: 8 AMS
 SG_ temperature_value_5 : 0|16@1+ (0.01,0) [0|0] "ºC" Vector__XXX
 SG_ temperature_value_6 : 16|16@1+ (0.01,0) [0|0] "ºC" Vector__XXX
 SG_ temperature_maximum : 32|16@1+ (0.01,0) [0|0] "ºC" Vector__XXX
 SG_ temperature_delta : 48|16@1+ (0.01,0) [0|0] "ºC" Vector__XXX

BO_ 359 Slave_10_MSC_ID_1: 8 AMS
 SG_ module_voltage_sum : 0|16@1+ (1,0) [0|0] "" Vector__XXX
 SG_ module_voltage_avg : 16|16@1+ (1,0) [0|0] "" Vector__XXX
 SG_ module_voltage_min : 32|16@1+ (1,0) [0|0] "" Vector__XXX
 SG_ module_voltage_max : 48|16@1+ (1,0) [0|0] "" Vector__XXX

BO_ 360 Slave_10_MSC_ID_2: 8 AMS
 SG_ module_voltage_delta : 0|16@1+ (1,0) [0|0] "" Vector__XXX
 SG_ module_ic_voltage : 16|16@1+ (1,0) [0|0] "" Vector__XXX
 SG_ module_open_wire : 32|8@1+ (1,0) [0|0] "" Vector__XXX
 SG_ module_ic_temperature : 40|16@1+ (1,0) [0|0] "" Vector__XXX

BO_ 361 Slave_11_Voltage_ID_1: 8 AMS
 SG_ cell_voltage_1 : 0|16@1+ (0.001,0) [0|0] "V" Vector__XXX
 SG_ cell_voltage_2 : 16|16@1+ (0.001,0) [0|0] "V" Vector__XXX
 SG_ cell_voltage_3 : 32|16@1+ (0.001,0) [0|0] "V" Vector__XXX
 SG_ cell_voltage_4 : 48|16@1+ (0.001,0) [0|0] "V" Vector__XXX

BO_ 368 Slave_11_Voltage_ID_2: 8 AMS
 SG_ cell_voltage_5 : 0|16@1+ (0.001,0) [0|0] "V" Vector__XXX
 SG_ cell_voltage_6 : 16|16@1+ (0.001,0) [0|0] "V" Vector__XXX
 SG_ cell_voltage_7 : 32|16@1+ (0.001,0) [0|0] "V" Vector__XXX
 SG_ cell_voltage_8 : 48|16@1+ (0.001,0) [0|0] "V" Vector__XXX

BO_ 369 Slave_11_Voltage_ID_3: 8 AMS
 SG_ cell_voltage_9 : 0|16@1+ (0.001,0) [0|0] "V" Vector__XXX
 SG_ cell_voltage_10 : 16|16@1+ (0.001,0) [0|0] "V" Vector__XXX
 SG_ cell_voltage_11 : 32|16@1+ (0.001,0) [0|0] "V" Vector__XXX
 SG_ cell_voltage_12 : 48|16@1+ (0.001,0) [0|0] "V" Vector__XXX

BO_ 370 Slave_11_Temperature_ID_1: 8 AMS
 SG_ temperature_value_1 : 0|16@1+ (0.01,0) [0|0] "ºC" Vector__XXX
 SG_ temperature_value_2 : 16|16@1+ (0.01,0) [0|0] "ºC" Vector__XXX
 SG_ temperature_value_3 : 32|16@1+ (0.01,0) [0|0] "ºC" Vector__XXX
 SG_ temperature_value_4 : 48|16@1+ (0.01,0) [0|0] "ºC" Vector__XXX

BO_ 371 Slave_11_Temperature_ID_2: 8 AMS
 SG_ temperature_value_5 : 0|16@1+ (0.01,0) [0|0] "ºC" Vector__XXX
 SG_ temperature_value_6 : 16|16@1+ (0.01,0) [0|0] "ºC" Vector__XXX
 SG_ temperature_maximum : 32|16@1+ (0.01,0) [0|0] "ºC" Vector__XXX
 SG_ temperature_delta : 48|16@1+ (0.01,0) [0|0] "ºC" Vector__XXX

BO_ 372 Slave_11_MSC_ID_1: 8 AMS
 SG_ module_voltage_sum : 0|16@1+ (1,0) [0|0] "" Vector__XXX
 SG_ module_voltage_avg : 16|16@1+ (1,0) [0|0] "" Vector__XXX
 SG_ module_voltage_min : 32|16@1+ (1,0) [0|0] "" Vector__XXX
 SG_ module_voltage_max : 48|16@1+ (1,0) [0|0] "" Vector__XXX

BO_ 373 Slave_11_MSC_ID_2: 8 AMS
 SG_ module_voltage_delta : 0|16@1+ (1,0) [0|0] "" Vector__XXX
 SG_ module_ic_voltage : 16|16@1+ (1,0) [0|0] "" Vector__XXX
 SG_ module_open_wire : 32|8@1+ (1,0) [0|0] "" Vector__XXX
 SG_ module_ic_temperature : 40|16@1+ (1,0) [0|0] "" Vector__XXX

BO_ 374 Slave_12_Voltage_ID_1: 8 AMS
 SG_ cell_voltage_1 : 0|16@1+ (0.001,0) [0|0] "V" Vector__XXX
 SG_ cell_voltage_2 : 16|16@1+ (0.001,0) [0|0] "V" Vector__XXX
 SG_ cell_voltage_3 : 32|16@1+ (0.001,0) [0|0] "V" Vector__XXX
 SG_ cell_voltage_4 : 48|16@1+ (0.001,0) [0|0] "V" Vector__XXX

BO_ 375 Slave_12_Voltage_ID_2: 8 AMS
 SG_ cell_voltage_5 : 0|16@1+ (0.001,0) [0|0] "V" Vector__XXX
 SG_ cell_voltage_6 : 16|16@1+ (0.001,0) [0|0] "V" Vector__XXX
 SG_ cell_voltage_7 : 32|16@1+ (0.001,0) [0|0] "V" Vector__XXX
 SG_ cell_voltage_8 : 48|16@1+ (0.001,0) [0|0] "V" Vector__XXX

BO_ 376 Slave_12_Voltage_ID_3: 8 AMS
 SG_ cell_voltage_9 : 0|16@1+ (0.001,0) [0|0] "V" Vector__XXX
 SG_ cell_voltage_10 : 16|16@1+ (0.001,0) [0|0] "V" Vector__XXX
 SG_ cell_voltage_11 : 32|16@1+ (0.001,0) [0|0] "V" Vector__XXX
 SG_ cell_voltage_12 : 48|16@1+ (0.001,0) [0|0] "V" Vector__XXX

BO_ 377 Slave_12_Temperature_ID_1: 8 AMS
 SG_ temperature_value_1 : 0|16@1+ (0.01,0) [0|0] "ºC" Vector__XXX
 SG_ temperature_value_2 : 16|16@1+ (0.01,0) [0|0] "ºC" Vector__XXX
 SG_ temperature_value_3 : 32|16@1+ (0.01,0) [0|0] "ºC" Vector__XXX
 SG_ temperature_value_4 : 48|16@1+ (0.01,0) [0|0] "ºC" Vector__XXX

BO_ 384 Slave_12_Temperature_ID_2: 8 AMS
 SG_ temperature_value_5 : 0|16@1+ (0.01,0) [0|0] "ºC" Vector__XXX
 SG_ temperature_value_6 : 16|16@1+ (0.01,0) [0|0] "ºC" Vector__XXX
 SG_ temperature_maximum : 32|16@1+ (0.01,0) [0|0] "ºC" Vector__XXX
 SG_ temperature_delta : 48|16@1+ (0.01,0) [0|0] "ºC" Vector__XXX

BO_ 385 Slave_12_MSC_ID_1: 8 AMS
 SG_ module_voltage_sum : 0|16@1+ (1,0) [0|0] "" Vector__XXX
 SG_ module_voltage_avg : 16|16@1+ (1,0) [0|0] "" Vector__XXX
 SG_ module_voltage_min : 32|16@1+ (1,0) [0|0] "" Vector__XXX
 SG_ module_voltage_max : 48|16@1+ (1,0) [0|0] "" Vector__XXX

BO_ 386 Slave_12_MSC_ID_2: 8 AMS
 SG_ module_voltage_delta : 0|16@1+ (1,0) [0|0] "" Vector__XXX
 SG_ module_ic_voltage : 16|16@1+ (1,0) [0|0] "" Vector__XXX
 SG_ module_open_wire : 32|8@1+ (1,0) [0|0] "" Vector__XXX
 SG_ module_ic_temperature : 40|16@1+ (1,0) [0|0] "" Vector__XXX

BO_ 1793 Master_MSC_ID_1: 8 AMS
 SG_ mcu_vref : 0|8@1+ (0.01,2) [0|0] "V" Vector__XXX
 SG_ mcu_temperature : 8|8@1+ (1,0) [0|0] "ºC" Vector__XXX
 SG_ ams_current_draw : 16|16@1+ (0.001,0) [0|65535] "A" Vector__XXX

BA_DEF_  "BusType" STRING ;
BA_DEF_DEF_  "BusType" "CAN";
